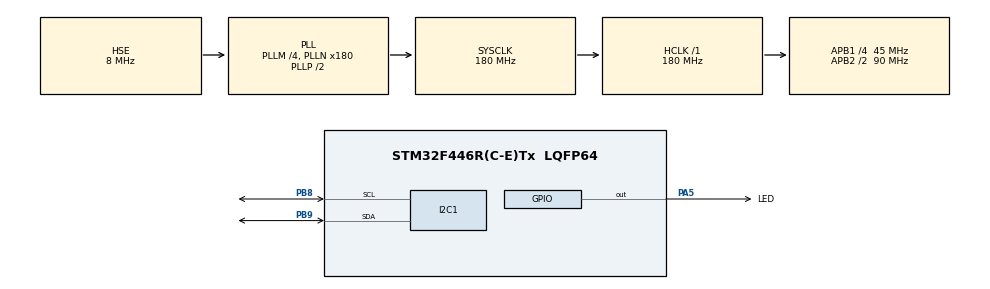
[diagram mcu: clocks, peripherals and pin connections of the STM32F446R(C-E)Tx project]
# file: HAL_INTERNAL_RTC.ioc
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Mcu.Family=STM32F4
Mcu.Name=STM32F446R(C-E)Tx
Mcu.Package=LQFP64
NVIC.PriorityGroup=NVIC_PRIORITYGROUP_4
NVIC.RTC_Alarm_IRQn=true\:0\:0\:false\:false\:true\:true\:true
PA5.GPIO_Label=LED
PA5.Signal=GPIO_Output
PB8.Mode=I2C
PB8.Signal=I2C1_SCL
PB9.Mode=I2C
PB9.Signal=I2C1_SDA
PC14-OSC32_IN.Mode=LSE-External-Oscillator
PC14-OSC32_IN.Signal=RCC_OSC32_IN
PC15-OSC32_OUT.Mode=LSE-External-Oscillator
PC15-OSC32_OUT.Signal=RCC_OSC32_OUT
PH0-OSC_IN.Mode=HSE-External-Oscillator
PH0-OSC_IN.Signal=RCC_OSC_IN
PH1-OSC_OUT.Mode=HSE-External-Oscillator
PH1-OSC_OUT.Signal=RCC_OSC_OUT
ProjectManager.HeapSize=0x200
ProjectManager.StackSize=0x400
ProjectManager.TargetToolchain=STM32CubeIDE
RCC.AHBFreq_Value=180000000
RCC.APB1CLKDivider=RCC_HCLK_DIV4
RCC.APB1Freq_Value=45000000
RCC.APB1TimFreq_Value=90000000
RCC.APB2CLKDivider=RCC_HCLK_DIV2
RCC.APB2Freq_Value=90000000
RCC.APB2TimFreq_Value=180000000
RCC.CortexFreq_Value=180000000
RCC.HCLKFreq_Value=180000000
RCC.HSE_VALUE=8000000
RCC.PLLM=4
RCC.PLLN=180
RCC.PLLSourceVirtual=RCC_PLLSOURCE_HSE
RCC.RCC_RTC_Clock_SourceVirtual=RCC_RTCCLKSOURCE_LSE
RCC.SYSCLKFreq_VALUE=180000000
RCC.SYSCLKSource=RCC_SYSCLKSOURCE_PLLCLK
RCC.USBFreq_Value=180000000
RCC.VCOOutputFreq_Value=360000000
RTC.Alarm=RTC_ALARM_A
RTC.AlarmDateWeekDay=12
RTC.Date=12
RTC.Format=RTC_FORMAT_BCD
RTC.Hours=13
RTC.Hours_A=13
RTC.Minutes=45
RTC.Minutes_A=47
RTC.Month=RTC_MONTH_SEPTEMBER
RTC.Seconds=50
RTC.WeekDay=RTC_WEEKDAY_SATURDAY
RTC.Year=20
VP_RTC_VS_RTC_Activate.Mode=RTC_Enabled
VP_RTC_VS_RTC_Alarm_A_Intern.Mode=Alarm A
VP_RTC_VS_RTC_Calendar.Mode=RTC_Calendar
board=custom

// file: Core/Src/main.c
/* USER CODE BEGIN Header */
/**
  ******************************************************************************
  * @file           : main.c
  * @brief          : Main program body
  ******************************************************************************
  * @attention
  *
  * <h2><center>&copy; Copyright (c) 2020 STMicroelectronics.
  * All rights reserved.</center></h2>
  *
  * This software component is licensed by ST under BSD 3-Clause license,
  * the "License"; You may not use this file except in compliance with the
  * License. You may obtain a copy of the License at:
  *                        opensource.org/licenses/BSD-3-Clause
  *
  ******************************************************************************
  */
/* USER CODE END Header */
#include "main.h"

/* USER CODE BEGIN Includes */
#include "i2c-lcd.h"
#include <stdio.h>
/* USER CODE END Includes */

I2C_HandleTypeDef hi2c1;

RTC_HandleTypeDef hrtc;

/* USER CODE BEGIN PV */
char time[10],date[10];

/* USER CODE END PV */

void SystemClock_Config(void);
static void MX_GPIO_Init(void);
static void MX_I2C1_Init(void);
static void MX_RTC_Init(void);

/* USER CODE BEGIN 0 */
void set_time(void){

	  RTC_TimeTypeDef sTime = {0};
	  RTC_DateTypeDef sDate = {0};

	/** Initialize RTC and set the Time and Date
	  */
	  sTime.Hours = 0x14;
	  sTime.Minutes = 0x17;
	  sTime.Seconds = 0x50;
	  sTime.DayLightSaving = RTC_DAYLIGHTSAVING_NONE;
	  sTime.StoreOperation = RTC_STOREOPERATION_RESET;
	  if (HAL_RTC_SetTime(&hrtc, &sTime, RTC_FORMAT_BCD) != HAL_OK)
	  {
	    Error_Handler();
	  }
	  sDate.WeekDay = RTC_WEEKDAY_SATURDAY;
	  sDate.Month = RTC_MONTH_SEPTEMBER;
	  sDate.Date = 0x12;
	  sDate.Year = 0x20;

	  if (HAL_RTC_SetDate(&hrtc, &sDate, RTC_FORMAT_BCD) != HAL_OK)
	  {
	    Error_Handler();
	  }

	  HAL_RTCEx_BKUPWrite(&hrtc, RTC_BKP_DR1, 0x32F2);	//	Backup register
}

void set_alarm(void){

	 RTC_AlarmTypeDef sAlarm = {0};

	 /** Enable the Alarm A
	  */
	  sAlarm.AlarmTime.Hours = 0x14;
	  sAlarm.AlarmTime.Minutes = 0x18;
	  sAlarm.AlarmTime.Seconds = 0x0;
	  sAlarm.AlarmTime.SubSeconds = 0x0;
	  sAlarm.AlarmTime.DayLightSaving = RTC_DAYLIGHTSAVING_NONE;
	  sAlarm.AlarmTime.StoreOperation = RTC_STOREOPERATION_RESET;
	  sAlarm.AlarmMask = RTC_ALARMMASK_NONE;
	  sAlarm.AlarmSubSecondMask = RTC_ALARMSUBSECONDMASK_ALL;
	  sAlarm.AlarmDateWeekDaySel = RTC_ALARMDATEWEEKDAYSEL_DATE;
	  sAlarm.AlarmDateWeekDay = 0x12;
	  sAlarm.Alarm = RTC_ALARM_A;
	  if (HAL_RTC_SetAlarm_IT(&hrtc, &sAlarm, RTC_FORMAT_BCD) != HAL_OK)
	  {
	    Error_Handler();
	  }
}

void get_time(void){

	RTC_DateTypeDef gDate ={0};
	RTC_TimeTypeDef gTime ={0};

	HAL_RTC_GetTime(&hrtc, &gTime, RTC_FORMAT_BIN);	//	Get the RTC current time value
	HAL_RTC_GetDate(&hrtc, &gDate, RTC_FORMAT_BIN);	//	Get the RTC current date value

	sprintf(time,"%02d:%02d:%02d",gTime.Hours,gTime.Minutes,gTime.Seconds);		//	Display time format:  hh:mm:ss
	sprintf(date,"%02d:%02d:%02d",gDate.Date,gDate.Month,gDate.Year+2000);		//	Display date format:  dd:mm:yy

}

void HAL_RTC_AlarmAEventCallback(RTC_HandleTypeDef *hrtc)
{
HAL_GPIO_TogglePin(LED_GPIO_Port, LED_Pin);
}
/* USER CODE END 0 */

int main(void)
{

  /* MCU Configuration--------------------------------------------------------*/

  /* Reset of all peripherals, Initializes the Flash interface and the Systick. */
  HAL_Init();

  /* Configure the system clock */
  SystemClock_Config();

  /* Initialize all configured peripherals */
  MX_GPIO_Init();
  MX_I2C1_Init();
  MX_RTC_Init();
  /* USER CODE BEGIN 2 */
  lcd_init();

  if (HAL_RTCEx_BKUPRead(&hrtc, RTC_BKP_DR1)!=0x32F2)
	  set_time();

set_alarm();

  /* USER CODE END 2 */

  /* Infinite loop */
  /* USER CODE BEGIN WHILE */
  while (1)
  {
	  get_time();
	  lcd_send_cmd(0x80);
	  lcd_send_string(time);
	  lcd_send_cmd(0xC0);
	  lcd_send_string(date);
	  HAL_Delay(100);

    /* USER CODE END WHILE */

  }
}

void SystemClock_Config(void)
{
  RCC_OscInitTypeDef RCC_OscInitStruct = {0};
  RCC_ClkInitTypeDef RCC_ClkInitStruct = {0};
  RCC_PeriphCLKInitTypeDef PeriphClkInitStruct = {0};

  /** Configure the main internal regulator output voltage
  */
  __HAL_RCC_PWR_CLK_ENABLE();
  __HAL_PWR_VOLTAGESCALING_CONFIG(PWR_REGULATOR_VOLTAGE_SCALE1);
  /** Initializes the RCC Oscillators according to the specified parameters
  * in the RCC_OscInitTypeDef structure.
  */
  RCC_OscInitStruct.OscillatorType = RCC_OSCILLATORTYPE_HSE|RCC_OSCILLATORTYPE_LSE;
  RCC_OscInitStruct.HSEState = RCC_HSE_ON;
  RCC_OscInitStruct.LSEState = RCC_LSE_ON;
  RCC_OscInitStruct.PLL.PLLState = RCC_PLL_ON;
  RCC_OscInitStruct.PLL.PLLSource = RCC_PLLSOURCE_HSE;
  RCC_OscInitStruct.PLL.PLLM = 4;
  RCC_OscInitStruct.PLL.PLLN = 180;
  RCC_OscInitStruct.PLL.PLLP = RCC_PLLP_DIV2;
  RCC_OscInitStruct.PLL.PLLQ = 2;
  RCC_OscInitStruct.PLL.PLLR = 2;
  if (HAL_RCC_OscConfig(&RCC_OscInitStruct) != HAL_OK)
  {
    Error_Handler();
  }
  /** Activate the Over-Drive mode
  */
  if (HAL_PWREx_EnableOverDrive() != HAL_OK)
  {
    Error_Handler();
  }
  /** Initializes the CPU, AHB and APB buses clocks
  */
  RCC_ClkInitStruct.ClockType = RCC_CLOCKTYPE_HCLK|RCC_CLOCKTYPE_SYSCLK
                              |RCC_CLOCKTYPE_PCLK1|RCC_CLOCKTYPE_PCLK2;
  RCC_ClkInitStruct.SYSCLKSource = RCC_SYSCLKSOURCE_PLLCLK;
  RCC_ClkInitStruct.AHBCLKDivider = RCC_SYSCLK_DIV1;
  RCC_ClkInitStruct.APB1CLKDivider = RCC_HCLK_DIV4;
  RCC_ClkInitStruct.APB2CLKDivider = RCC_HCLK_DIV2;

  if (HAL_RCC_ClockConfig(&RCC_ClkInitStruct, FLASH_LATENCY_5) != HAL_OK)
  {
    Error_Handler();
  }
  PeriphClkInitStruct.PeriphClockSelection = RCC_PERIPHCLK_RTC;
  PeriphClkInitStruct.RTCClockSelection = RCC_RTCCLKSOURCE_LSE;
  if (HAL_RCCEx_PeriphCLKConfig(&PeriphClkInitStruct) != HAL_OK)
  {
    Error_Handler();
  }
}

static void MX_I2C1_Init(void)
{

  hi2c1.Instance = I2C1;
  hi2c1.Init.ClockSpeed = 100000;
  hi2c1.Init.DutyCycle = I2C_DUTYCYCLE_2;
  hi2c1.Init.OwnAddress1 = 0;
  hi2c1.Init.AddressingMode = I2C_ADDRESSINGMODE_7BIT;
  hi2c1.Init.DualAddressMode = I2C_DUALADDRESS_DISABLE;
  hi2c1.Init.OwnAddress2 = 0;
  hi2c1.Init.GeneralCallMode = I2C_GENERALCALL_DISABLE;
  hi2c1.Init.NoStretchMode = I2C_NOSTRETCH_DISABLE;
  if (HAL_I2C_Init(&hi2c1) != HAL_OK)
  {
    Error_Handler();
  }

}

static void MX_RTC_Init(void)
{

  /** Initialize RTC Only
  */
  hrtc.Instance = RTC;
  hrtc.Init.HourFormat = RTC_HOURFORMAT_24;
  hrtc.Init.AsynchPrediv = 127;
  hrtc.Init.SynchPrediv = 255;
  hrtc.Init.OutPut = RTC_OUTPUT_DISABLE;
  hrtc.Init.OutPutPolarity = RTC_OUTPUT_POLARITY_HIGH;
  hrtc.Init.OutPutType = RTC_OUTPUT_TYPE_OPENDRAIN;
  if (HAL_RTC_Init(&hrtc) != HAL_OK)
  {
    Error_Handler();
  }

  /** Initialize RTC and set the Time and Date
  */

}

static void MX_GPIO_Init(void)
{
  GPIO_InitTypeDef GPIO_InitStruct = {0};

  /* GPIO Ports Clock Enable */
  __HAL_RCC_GPIOC_CLK_ENABLE();
  __HAL_RCC_GPIOH_CLK_ENABLE();
  __HAL_RCC_GPIOA_CLK_ENABLE();
  __HAL_RCC_GPIOB_CLK_ENABLE();

  /*Configure GPIO pin Output Level */
  HAL_GPIO_WritePin(LED_GPIO_Port, LED_Pin, GPIO_PIN_RESET);

  /*Configure GPIO pin : LED_Pin */
  GPIO_InitStruct.Pin = LED_Pin;
  GPIO_InitStruct.Mode = GPIO_MODE_OUTPUT_PP;
  GPIO_InitStruct.Pull = GPIO_NOPULL;
  GPIO_InitStruct.Speed = GPIO_SPEED_FREQ_LOW;
  HAL_GPIO_Init(LED_GPIO_Port, &GPIO_InitStruct);

}

void Error_Handler(void)
{
}

/************************ (C) COPYRIGHT STMicroelectronics *****END OF FILE****/
